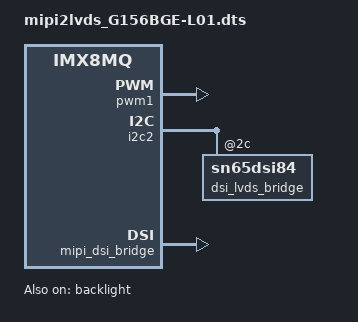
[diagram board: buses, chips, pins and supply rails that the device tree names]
/dts-v1/;
/plugin/;
/ {
	compatible = "fsl,imx8mq";

	fragment@0 {
		target = <&pwm1>;
		__overlay__ {
			status = "okay";
		};
	};
	fragment@1 {
		target = <&backlight>;
		__overlay__ {
			status = "okay";
			pwms = <&pwm1 0 5000000 0>;
                        power-sequence-reverse;
                        disable_delay = <15>;
                        minimal-brightness-level = <30>;
		};
	};
	fragment@2 {
		target = <&i2c2>;
		__overlay__ {
			status = "okay";
			dsi_lvds_bridge: sn65dsi84@2c {
				status = "okay";
				lvds-clk-rate = <70000000>;
				lvds-format = <2>;
				lvds-bpp = <24>;
				lvds-width-mm = <344>;
				lvds-height-mm = <193>;
				sync_delay = <33>;

				t1=<0>;
				t2=<1>;
				t3=<500>;
				t4=<200>;
				t5=<1>;
				t6=<0>;
				t7=<1000>;

				bpc=<8>;
				bus-format = <0x100a>;
				dsi,flags = <0x3>;
				dsi,format = <0>;
				dsi-lanes = <4>;

				display-timings {
					lvds {
						clock-frequency = <70000000>;
						hactive = <1360>;
						vactive = <768>;
						hfront-porch = <50>;
						hback-porch = <50>;
						hsync-len = <34>;
						vfront-porch = <12>;
						vsync-len = <8>;
						vback-porch = <12>;
						hsync-active = <0>;
						vsync-active = <0>;
						de-active = <0>;
						pixelclk-active = <0>;
					};
				};
			};
		};
	};
	fragment@3 {
		target = <&mipi_dsi_bridge>;
		__overlay__ {
			status = "okay";
			//best-match;
			panel@0 {
				status = "disabled";
			};
		};
	};
	fragment@4 {
		target = <&mipi_dsi>;
		__overlay__ {
			sync-pol = <1>;
			pwr-delay = <100>;
			//best-match;
		};
	};
	fragment@5 {
		target = <&lcdif>;
		__overlay__ {
			max-res = <4096>, <4096>;
		};
	};

};
